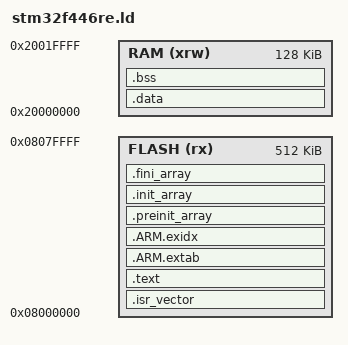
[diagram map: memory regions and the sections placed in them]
ENTRY(Reset_Handler)

MEMORY
{
    FLASH (rx)  : ORIGIN = 0x08000000, LENGTH = 512K
    RAM   (xrw) : ORIGIN = 0x20000000, LENGTH = 128K
}

_estack = ORIGIN(RAM) + LENGTH(RAM);

SECTIONS
{
    .isr_vector :
    {
        KEEP(*(.isr_vector))
    } > FLASH

    .text :
    {
        . = ALIGN(4);
        KEEP(*(.init))
        KEEP(*(.fini))
        *(.text*)
        *(.glue_7)
        *(.glue_7t)
        *(.eh_frame)
        *(.rodata*)
        . = ALIGN(4);
        _etext = .;
    } > FLASH

    .ARM.extab :
    {
        *(.ARM.extab* .gnu.linkonce.armextab.*)
    } > FLASH

    .ARM.exidx :
    {
        __exidx_start = .;
        *(.ARM.exidx* .gnu.linkonce.armexidx.*)
        __exidx_end = .;
    } > FLASH

    .preinit_array :
    {
        . = ALIGN(4);
        PROVIDE_HIDDEN(__preinit_array_start = .);
        KEEP(*(.preinit_array*))
        PROVIDE_HIDDEN(__preinit_array_end = .);
    } > FLASH

    .init_array :
    {
        . = ALIGN(4);
        PROVIDE_HIDDEN(__init_array_start = .);
        KEEP(*(SORT(.init_array.*)))
        KEEP(*(.init_array*))
        PROVIDE_HIDDEN(__init_array_end = .);
    } > FLASH

    .fini_array :
    {
        . = ALIGN(4);
        PROVIDE_HIDDEN(__fini_array_start = .);
        KEEP(*(SORT(.fini_array.*)))
        KEEP(*(.fini_array*))
        PROVIDE_HIDDEN(__fini_array_end = .);
    } > FLASH

    _sidata = LOADADDR(.data);

    .data : AT(ADDR(.fini_array) + SIZEOF(.fini_array))
    {
        . = ALIGN(4);
        _sdata = .;
        *(.data*)
        . = ALIGN(4);
        _edata = .;
    } > RAM

    .bss (NOLOAD) :
    {
        . = ALIGN(4);
        _sbss = .;
        *(.bss*)
        *(COMMON)
        . = ALIGN(4);
        _ebss = .;
    } > RAM

    . = ALIGN(4);
    end = .;
    _end = .;
    
    /DISCARD/ :
    {
        *(.note*)
        *(.comment*)
    }
}
